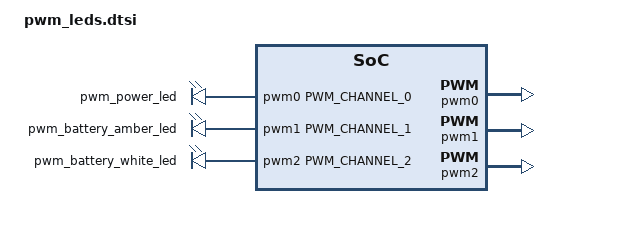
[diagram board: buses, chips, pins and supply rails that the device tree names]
/* Copyright 2024 The ChromiumOS Authors
 * Use of this source code is governed by a BSD-style license that can be
 * found in the LICENSE file.
 */

/ {
	pwmleds {
		compatible = "pwm-leds";
		pwm_power_led: pwm_power_led {
			pwms = <&pwm0 PWM_CHANNEL_0 PWM_HZ(324) PWM_POLARITY_INVERTED>;
		};
		pwm_battery_amber_led: pwm_battery_amber_led {
			pwms = <&pwm1 PWM_CHANNEL_1 PWM_HZ(324) PWM_POLARITY_INVERTED>;
		};
		pwm_battery_white_led: pwm_battery_white_led {
			pwms = <&pwm2 PWM_CHANNEL_2 PWM_HZ(324) PWM_POLARITY_INVERTED>;
		};
	};

	cros-pwmleds {
		compatible = "cros-ec,pwm-leds";

		leds = <&pwm_power_led>;
		leds = <&pwm_battery_amber_led>;
		leds = <&pwm_battery_white_led>;
	};
};

&pwm0 {
	status = "okay";
	prescaler-cx = <PWM_PRESCALER_C4>;
	pinctrl-0 = <&pwm0_gpa0_default>;
	pinctrl-names = "default";
};

&pwm1 {
	status = "okay";
	prescaler-cx = <PWM_PRESCALER_C4>;
	pinctrl-0 = <&pwm1_gpa1_default>;
	pinctrl-names = "default";
};

&pwm2 {
	status = "okay";
	prescaler-cx = <PWM_PRESCALER_C4>;
	pinctrl-0 = <&pwm2_gpa2_default>;
	pinctrl-names = "default";
};
